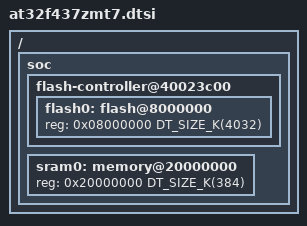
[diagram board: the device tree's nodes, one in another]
/*
 * Copyright (c) 2024, Maxjta
 *
 * SPDX-License-Identifier: Apache-2.0
 */

#include <mem.h>
#include <at/at32f435_437/at32f435_437.dtsi>

/ {
	soc {
		flash-controller@40023c00 {
			flash0: flash@8000000 {
				reg = <0x08000000 DT_SIZE_K(4032)>;
			};
		};

		sram0: memory@20000000 {
			reg = <0x20000000 DT_SIZE_K(384)>;
		};
	};
};
